# CYNTHION_SOC register map
Vendor: awtoau; File version: 1.0
Registers are 8-bit, read-write, no defined reset value unless marked. A register's access mark holds for its fields unless they carry their own. Offsets are from the block's base; [hi:lo] are bit positions; {n}, {i} and the like mark numbered series.

## BOARD_GPIO — board/gpio: 4 registers at 0xf0000600
Base 0xF0000600
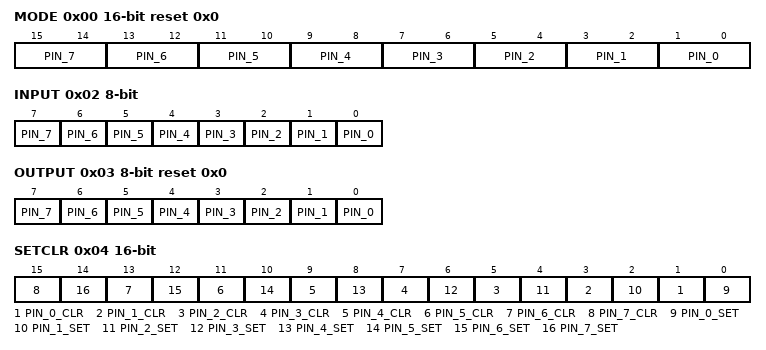
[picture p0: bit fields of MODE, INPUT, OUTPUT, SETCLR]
0x00 MODE 16-bit reset 0x0 — BOARD_GPIO.MODE, 16 bits at +0x00
  [2n+1:2n] PIN_{n} (n=0..7) — pin_{n} [{2n+1}:{2n}]
0x02 INPUT ro — BOARD_GPIO.INPUT, 8 bits at +0x02
  [n] PIN_{n} (n=0..7) — pin_{n} [{n}]
0x03 OUTPUT reset 0x0 — BOARD_GPIO.OUTPUT, 8 bits at +0x03
  [n] PIN_{n} (n=0..7) — pin_{n} [{n}]
0x04 SETCLR 16-bit wo — BOARD_GPIO.SETCLR, 16 bits at +0x04
  [2n+1] PIN_{n}_CLR (n=0..7) — pin_{n}_clr [{2n+1}]
  [2n] PIN_{n}_SET (n=0..7) — pin_{n}_set [{2n}]

## BOARD_I2C — board/i2c: 5 registers at 0xf0000610
Base 0xF0000610
0x00 PRER_LO reset 0x0 — BOARD_I2C.PRER_LO, 8 bits at +0x00
  [7:0] DATA — data [7:0]
0x01 PRER_HI reset 0x0 — BOARD_I2C.PRER_HI, 8 bits at +0x01
  [7:0] DATA — data [7:0]
0x02 CTR reset 0x0 — BOARD_I2C.CTR, 8 bits at +0x02
  [7:0] DATA — data [7:0]
0x03 TXR_RXR — BOARD_I2C.TXR_RXR, 8 bits at +0x03
  [7:0] DATA — data [7:0]
0x04 CR_SR — BOARD_I2C.CR_SR, 8 bits at +0x04
  [7:0] DATA — data [7:0]

## BOARD_SIDEBAND — board/sideband: 4 registers at 0xf0000618
Base 0xF0000618
0x00 CTRL reset 0x0 — BOARD_SIDEBAND.CTRL, 8 bits at +0x00
  [7:0] DATA — data [7:0]
0x01 TX reset 0x0 — BOARD_SIDEBAND.TX, 8 bits at +0x01
  [7:0] DATA — data [7:0]
0x02 RX ro — BOARD_SIDEBAND.RX, 8 bits at +0x02
  [7:0] DATA — data [7:0]
0x03 RXCNT ro — BOARD_SIDEBAND.RXCNT, 8 bits at +0x03
  [7:0] DATA — data [7:0]

## BOARD_ULPI — board/ulpi: 4 registers at 0xf000061c
Base 0xF000061C
0x00 ADDRESS reset 0x0 — BOARD_ULPI.ADDRESS, 6 bits at +0x00
  [5:0] ADDRESS — address [5:0]
0x01 DATA — BOARD_ULPI.DATA, 8 bits at +0x01
  [7:0] DATA — data [7:0]
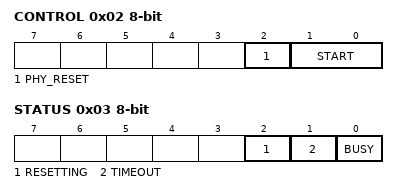
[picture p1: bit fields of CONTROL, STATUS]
0x02 CONTROL wo — BOARD_ULPI.CONTROL, 3 bits at +0x02
  [2] PHY_RESET — phy_reset [2]
  [1:0] START — start [1:0]
0x03 STATUS ro — BOARD_ULPI.STATUS, 3 bits at +0x03
  [2] RESETTING — resetting [2]
  [1] TIMEOUT — timeout [1]
  [0] BUSY — busy [0]

## BOARD_I2C_MUX — board/i2c_mux: 2 registers at 0xf0000620
Base 0xF0000620
0x00 SELECT reset 0x2 — BOARD_I2C_MUX.SELECT, 2 bits at +0x00
  [1:0] SELECT — select [1:0]
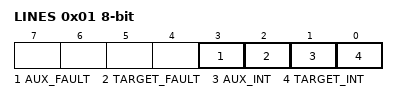
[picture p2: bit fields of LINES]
0x01 LINES ro — BOARD_I2C_MUX.LINES, 4 bits at +0x01
  [3] AUX_FAULT — aux_fault [3]
  [2] TARGET_FAULT — target_fault [2]
  [1] AUX_INT — aux_int [1]
  [0] TARGET_INT — target_int [0]

## BOARD_VBUS — board/vbus: 1 register at 0xf0000624
Base 0xF0000624
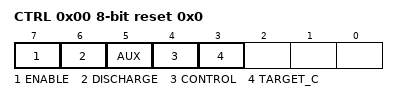
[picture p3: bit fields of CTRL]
0x00 CTRL reset 0x0 — BOARD_VBUS.CTRL, 8 bits at +0x00
  [7] ENABLE — enable [7]
  [6] DISCHARGE — discharge [6]
  [5] AUX — aux [5]
  [4] CONTROL — control [4]
  [3] TARGET_C — target_c [3]

## BOARD_FABRIC — board/fabric: 2 registers at 0xf0000640
Base 0xF0000640
0x00 DIE 16-bit ro — BOARD_FABRIC.DIE, 9 bits at +0x00
  [8:0] VALUE — value [8:0]
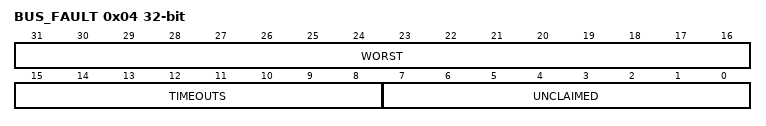
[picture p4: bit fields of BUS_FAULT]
0x04 BUS_FAULT 32-bit ro — BOARD_FABRIC.BUS_FAULT, 32 bits at +0x04
  [31:16] WORST — worst [31:16]
  [15:8] TIMEOUTS — timeouts [15:8]
  [7:0] UNCLAIMED — unclaimed [7:0]

## BOARD_CLOCKS — board/clocks: 2 registers at 0xf0000660
Base 0xF0000660
0x00 SYNC_KHZ 32-bit ro — BOARD_CLOCKS.SYNC_KHZ, 32 bits at +0x00
  [31:0] VALUE — value [31:0]
0x04 STATUS 32-bit ro — BOARD_CLOCKS.STATUS, 32 bits at +0x04
  [31:0] VALUE — value [31:0]

## HYPERRAM — hyperram: 41 registers at 0xf0000800
Base 0xF0000800
0x00 ID 32-bit ro — HYPERRAM.ID, 32 bits at +0x00
  [31:0] V — v [31:0]
0x04 CK_KHZ 32-bit ro — HYPERRAM.CK_KHZ, 32 bits at +0x04
  [31:0] V — v [31:0]
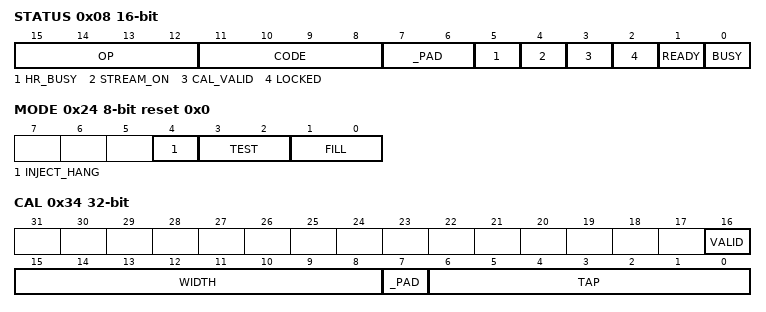
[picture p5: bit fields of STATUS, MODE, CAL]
0x08 STATUS 16-bit ro — HYPERRAM.STATUS, 16 bits at +0x08
  [15:12] OP — op [15:12]
  [11:8] CODE — code [11:8]
  [7:6] _PAD — _pad [7:6]
  [5] HR_BUSY — hr_busy [5]
  [4] STREAM_ON — stream_on [4]
  [3] CAL_VALID — cal_valid [3]
  [2] LOCKED — locked [2]
  [1] READY — ready [1]
  [0] BUSY — busy [0]
0x0C CMD wo — HYPERRAM.CMD, 4 bits at +0x0c
  [3:0] OP — op [3:0]
0x0D CTRL wo — HYPERRAM.CTRL, 1 bits at +0x0d
  [0] ABORT — abort [0]
0x0E EVENTS reset 0x0 — HYPERRAM.EVENTS, 2 bits at +0x0e
  [1:0] V — v [1:0]
0x0F IRQ_EN reset 0x0 — HYPERRAM.IRQ_EN, 2 bits at +0x0f
  [1:0] V — v [1:0]
0x10 ERRORS 16-bit reset 0x0 — HYPERRAM.ERRORS, 13 bits at +0x10
  [12:0] V — v [12:0]
0x14 HR_ADDR 32-bit reset 0x0 — HYPERRAM.HR_ADDR, 23 bits at +0x14
  [22:0] V — v [22:0]
0x18 WIN_ADDR 16-bit reset 0x0 — HYPERRAM.WIN_ADDR, 12 bits at +0x18
  [11:0] V — v [11:0]
0x1C LEN 32-bit reset 0x0 — HYPERRAM.LEN, 24 bits at +0x1c
  [23:0] V — v [23:0]
0x20 FILL_VALUE 32-bit reset 0x0 — HYPERRAM.FILL_VALUE, 32 bits at +0x20
  [31:0] V — v [31:0]
0x24 MODE reset 0x0 — HYPERRAM.MODE, 5 bits at +0x24
  [4] INJECT_HANG — inject_hang [4]
  [3:2] TEST — test [3:2]
  [1:0] FILL — fill [1:0]
0x25 REG_SEL reset 0x2 — HYPERRAM.REG_SEL, 2 bits at +0x25
  [1:0] V — v [1:0]
0x26 LATENCY reset 0xD — HYPERRAM.LATENCY, 5 bits at +0x26
  [4:0] V — v [4:0]
0x27 DELAY reset 0x0 — HYPERRAM.DELAY, 7 bits at +0x27
  [6:0] V — v [6:0]
0x28 SEED 16-bit reset 0x0 — HYPERRAM.SEED, 16 bits at +0x28
  [15:0] V — v [15:0]
0x2A XOR 16-bit reset 0x0 — HYPERRAM.XOR, 16 bits at +0x2a
  [15:0] V — v [15:0]
0x2C BURST 16-bit reset 0x0 — HYPERRAM.BURST, 16 bits at +0x2c
  [15:0] V — v [15:0]
0x2E REG_WDATA 16-bit reset 0x8F2F — HYPERRAM.REG_WDATA, 16 bits at +0x2e
  [15:0] V — v [15:0]
0x30 REG_RDATA 16-bit ro — HYPERRAM.REG_RDATA, 16 bits at +0x30
  [15:0] V — v [15:0]
0x34 CAL 32-bit ro — HYPERRAM.CAL, 17 bits at +0x34
  [16] VALID — valid [16]
  [15:8] WIDTH — width [15:8]
  [7] _PAD — _pad [7]
  [6:0] TAP — tap [6:0]
{0x38+4i} CAL_MAP{i} 32-bit ro (i=0..3) — HYPERRAM.CAL_MAP{i}, 32 bits at +{0x38+4i}
  [31:0] V — v [31:0]
0x48 CYCLES 32-bit ro — HYPERRAM.CYCLES, 32 bits at +0x48
  [31:0] V — v [31:0]
0x4C WORDS 32-bit ro — HYPERRAM.WORDS, 32 bits at +0x4c
  [31:0] V — v [31:0]
0x50 XACTS 32-bit ro — HYPERRAM.XACTS, 32 bits at +0x50
  [31:0] V — v [31:0]
0x54 CHECKED 32-bit ro — HYPERRAM.CHECKED, 32 bits at +0x54
  [31:0] V — v [31:0]
0x58 ERRS 32-bit ro — HYPERRAM.ERRS, 32 bits at +0x58
  [31:0] V — v [31:0]
0x5C BAD_INDEX 32-bit ro — HYPERRAM.BAD_INDEX, 32 bits at +0x5c
  [31:0] V — v [31:0]
0x60 BAD_GOT_WANT 32-bit ro — HYPERRAM.BAD_GOT_WANT, 32 bits at +0x60
  [31:0] V — v [31:0]
0x64 BAD_BITS 16-bit ro — HYPERRAM.BAD_BITS, 16 bits at +0x64
  [15:0] V — v [15:0]
0x66 STATE 16-bit ro — HYPERRAM.STATE, 16 bits at +0x66
  [15:0] V — v [15:0]
0x68 MISSING 32-bit ro — HYPERRAM.MISSING, 32 bits at +0x68
  [31:0] V — v [31:0]
0x6C CK_COUNT 32-bit ro — HYPERRAM.CK_COUNT, 32 bits at +0x6c
  [31:0] V — v [31:0]
0x70 STREAM_BASE 32-bit reset 0x0 — HYPERRAM.STREAM_BASE, 22 bits at +0x70
  [21:0] V — v [21:0]
0x74 STREAM_MASK 32-bit reset 0xFFFFF — HYPERRAM.STREAM_MASK, 22 bits at +0x74
  [21:0] V — v [21:0]
0x78 STREAM_CTRL reset 0x0 — HYPERRAM.STREAM_CTRL, 1 bits at +0x78
  [0] V — v [0]
0x7C STREAM_LEVEL 32-bit ro — HYPERRAM.STREAM_LEVEL, 23 bits at +0x7c
  [22:0] V — v [22:0]

## INTC — intc: 2 registers at 0xf0000c00
Base 0xF0000C00
0x00 ENABLE 32-bit — INTC.ENABLE, 20 bits at +0x00
  [19:0] MASK — mask [19:0]
0x04 PENDING 32-bit — INTC.PENDING, 20 bits at +0x04
  [19:0] MASK — mask [19:0]

## USB_HOST — usb_host: 27 registers at 0xf0001000
Base 0xF0001000
0x00 ROLE — USB_HOST.ROLE, 2 bits at +0x00
  [1:0] V — v [1:0]
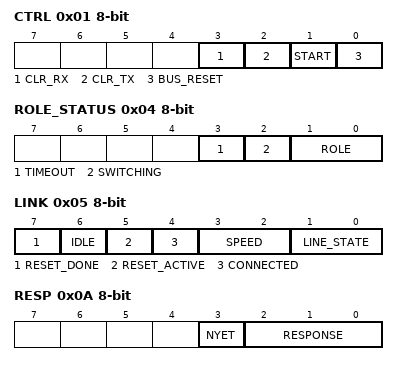
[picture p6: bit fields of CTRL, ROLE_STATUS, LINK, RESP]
0x01 CTRL wo — USB_HOST.CTRL, 4 bits at +0x01
  [3] CLR_RX — clr_rx [3]
  [2] CLR_TX — clr_tx [2]
  [1] START — start [1]
  [0] BUS_RESET — bus_reset [0]
0x02 IRQ_EN — USB_HOST.IRQ_EN, 4 bits at +0x02
  [3:0] V — v [3:0]
0x04 ROLE_STATUS ro — USB_HOST.ROLE_STATUS, 4 bits at +0x04
  [3] TIMEOUT — timeout [3]
  [2] SWITCHING — switching [2]
  [1:0] ROLE — role [1:0]
0x05 LINK ro — USB_HOST.LINK, 8 bits at +0x05
  [7] RESET_DONE — reset_done [7]
  [6] IDLE — idle [6]
  [5] RESET_ACTIVE — reset_active [5]
  [4] CONNECTED — connected [4]
  [3:2] SPEED — speed [3:2]
  [1:0] LINE_STATE — line_state [1:0]
0x06 EVENTS reset 0x0 — USB_HOST.EVENTS, 8 bits at +0x06
  [7:0] EV — ev [7:0]
0x07 RXPID ro — USB_HOST.RXPID, 8 bits at +0x07
  [7:0] PID — pid [7:0]
0x08 ADDR — USB_HOST.ADDR, 7 bits at +0x08
  [6:0] V — v [6:0]
0x09 EP — USB_HOST.EP, 7 bits at +0x09
  [6:0] V — v [6:0]
0x0A RESP ro — USB_HOST.RESP, 4 bits at +0x0a
  [3] NYET — nyet [3]
  [2:0] RESPONSE — response [2:0]
0x0C RXLEN_LO ro — USB_HOST.RXLEN_LO, 8 bits at +0x0c
  [7:0] V — v [7:0]
0x0D RXLEN_HI ro — USB_HOST.RXLEN_HI, 8 bits at +0x0d
  [7:0] V — v [7:0]
0x10 RX_DATA — USB_HOST.RX_DATA, 8 bits at +0x10
  [7:0] V — v [7:0]
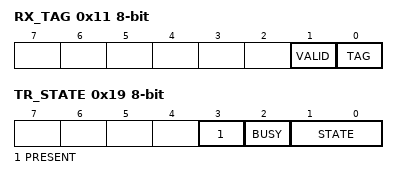
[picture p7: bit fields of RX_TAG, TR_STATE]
0x11 RX_TAG ro — USB_HOST.RX_TAG, 2 bits at +0x11
  [1] VALID — valid [1]
  [0] TAG — tag [0]
0x12 RX_LEVEL ro — USB_HOST.RX_LEVEL, 8 bits at +0x12
  [7:0] V — v [7:0]
0x14 TX_DATA wo — USB_HOST.TX_DATA, 8 bits at +0x14
  [7:0] V — v [7:0]
0x15 TX_LAST wo — USB_HOST.TX_LAST, 8 bits at +0x15
  [7:0] V — v [7:0]
0x16 TX_CMD wo — USB_HOST.TX_CMD, 8 bits at +0x16
  [7:0] V — v [7:0]
0x17 TX_LEVEL ro — USB_HOST.TX_LEVEL, 8 bits at +0x17
  [7:0] V — v [7:0]
0x18 TR_CTRL wo — USB_HOST.TR_CTRL, 4 bits at +0x18
  [3:0] V — v [3:0]
0x19 TR_STATE ro — USB_HOST.TR_STATE, 4 bits at +0x19
  [3] PRESENT — present [3]
  [2] BUSY — busy [2]
  [1:0] STATE — state [1:0]
0x1A TR_CNT_LO ro — USB_HOST.TR_CNT_LO, 8 bits at +0x1a
  [7:0] V — v [7:0]
0x1B TR_CNT_HI ro — USB_HOST.TR_CNT_HI, 8 bits at +0x1b
  [7:0] V — v [7:0]
0x1C TR_IDX_LO — USB_HOST.TR_IDX_LO, 8 bits at +0x1c
  [7:0] V — v [7:0]
0x1D TR_IDX_HI — USB_HOST.TR_IDX_HI, 8 bits at +0x1d
  [7:0] V — v [7:0]
0x1E TR_SEL — USB_HOST.TR_SEL, 3 bits at +0x1e
  [2:0] V — v [2:0]
0x1F TR_DATA ro — USB_HOST.TR_DATA, 8 bits at +0x1f
  [7:0] V — v [7:0]

## CLINT — clint: 5 registers at 0xf0800000
Base 0xF0800000
0x00 MSIP reset 0x0 — CLINT.MSIP, 1 bits at +0x00
  [0] PENDING — pending [0]
0x4000 MTIMECMP_LO 32-bit reset 0xFFFFFFFF — CLINT.MTIMECMP_LO, 32 bits at +0x4000
  [31:0] VALUE — value [31:0]
0x4004 MTIMECMP_HI 32-bit reset 0xFFFFFFFF — CLINT.MTIMECMP_HI, 32 bits at +0x4004
  [31:0] VALUE — value [31:0]
0xBFF8 MTIME_LO 32-bit ro — CLINT.MTIME_LO, 32 bits at +0xbff8
  [31:0] VALUE — value [31:0]
0xBFFC MTIME_HI 32-bit ro — CLINT.MTIME_HI, 32 bits at +0xbffc
  [31:0] VALUE — value [31:0]
